// Description: LIN Description file created using Vector's DaVinci Network Designer
// Created: 07 Sep 2007 14:37:29
// Author: visbr
// Version: 0.1
LIN_description_file;
LIN_protocol_version = "2.1";
LIN_language_version = "2.1";
LIN_speed = 19.2 kbps; // baudrate (1.0-20.0)

Channel_name = "ECM_LIN3";

Nodes
{
  Master: ECM_ECM_LIN3, 5 ms, 1 ms ;
  Slaves: ECPM_ECM_LIN3;
}

Signals {
   /* Signal_name : Size, Init, Publisher, Subscriber(s) */
  D_EWP_Setspeed : 13, 0, ECM_ECM_LIN3, ECPM_ECM_LIN3;
  D_EWP_Post_running_mode : 3, 0, ECM_ECM_LIN3, ECPM_ECM_LIN3;

  Setspeed : 8, 0, ECPM_ECM_LIN3, ECM_ECM_LIN3;
  Actual_speed : 8, 0, ECPM_ECM_LIN3, ECM_ECM_LIN3;
  Voltage : 8, 0, ECPM_ECM_LIN3, ECM_ECM_LIN3;
  Temperature : 8, 0, ECPM_ECM_LIN3, ECM_ECM_LIN3;
  Current : 8, 0, ECPM_ECM_LIN3, ECM_ECM_LIN3;
  Wakeup_status : 2, 0, ECPM_ECM_LIN3, ECM_ECM_LIN3;
  RPM_Monitoring : 2, 0, ECPM_ECM_LIN3, ECM_ECM_LIN3;
  Status_Emergency_mode : 2, 0, ECPM_ECM_LIN3, ECM_ECM_LIN3;
  Over_temperature : 2, 0, ECPM_ECM_LIN3, ECM_ECM_LIN3;
  Overcurren : 2, 0, ECPM_ECM_LIN3, ECM_ECM_LIN3;
  Dry_run : 2, 0, ECPM_ECM_LIN3, ECM_ECM_LIN3;
  Voltage_Error : 2, 0, ECPM_ECM_LIN3, ECM_ECM_LIN3;
  Deblocking : 2, 0, ECPM_ECM_LIN3, ECM_ECM_LIN3;
  Electrical_error : 1, 0, ECPM_ECM_LIN3, ECM_ECM_LIN3;
  Status_Post_running_mode : 3, 0, ECPM_ECM_LIN3, ECM_ECM_LIN3;
  Communication_error : 1, 0, ECPM_ECM_LIN3, ECM_ECM_LIN3;
}

/* ----------UNCONDITIONAL FRAME DEFINITIONS---------- */

Frames {
    EcmEcm_Lin3Fr02_ECM_LIN3 :0x31, ECM_ECM_LIN3 ,8{

      D_EWP_Setspeed ,0;
      D_EWP_Post_running_mode ,13;
   }

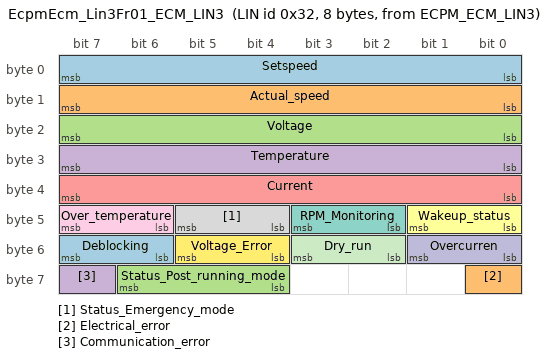
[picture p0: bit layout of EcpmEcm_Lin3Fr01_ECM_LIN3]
    EcpmEcm_Lin3Fr01_ECM_LIN3 :0x32, ECPM_ECM_LIN3 ,8{

    Setspeed ,0;
  Actual_speed ,8;
  Voltage ,16;
  Temperature ,24;
  Current ,32;
  Wakeup_status ,40;
  RPM_Monitoring ,42;
  Status_Emergency_mode ,44;
  Over_temperature ,46;
  Overcurren ,48;
  Dry_run ,50;
  Voltage_Error ,52;
  Deblocking ,54;
  Electrical_error ,56;
  Status_Post_running_mode ,60;
  Communication_error ,63;

   }

}

Node_attributes
{
  ECPM_ECM_LIN3
  {
    LIN_protocol = "2.1" ;
    configured_NAD = 0x06 ;
    initial_NAD = 0x06 ;
    product_id = 0x00,
               0x00,
         0x0 ;
    response_error = Communication_error ;
    P2_min = 100 ms ;
    ST_min = 20 ms ;
    N_As_timeout = 1000 ms ;
    N_Cr_timeout = 1000 ms ;
    configurable_frames
    {
      EcpmEcm_Lin3Fr01_ECM_LIN3;
      EcmEcm_Lin3Fr02_ECM_LIN3;
    }
  }
}

Schedule_tables
{

Ecm_Lin3DiagRequestSchedule_ECM_LIN3 {
    MasterReq delay 15.000 ms;
  }
  Ecm_Lin3DiagResponseSchedule_ECM_LIN3 {
    SlaveResp delay 15.000 ms;
  }
  Ecm_Lin3Schedule01_ECM_LIN3 {
    EcpmEcm_Lin3Fr01_ECM_LIN3 delay 15.000 ms;
    EcmEcm_Lin3Fr02_ECM_LIN3 delay 10.000 ms;

  }

}
